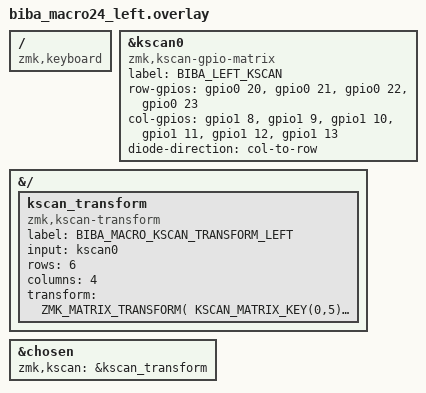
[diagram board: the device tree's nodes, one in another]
/dts-v1/;
/ {
    compatible = "zmk,keyboard";
};

/* LEFT PCB pins — replace with your actual Biba40 left-half pins */
&kscan0 {
    compatible = "zmk,kscan-gpio-matrix";
    label = "BIBA_LEFT_KSCAN";

    /* Example: old matrix 4 rows × 6 cols */
    row-gpios = <&gpio0 20 GPIO_ACTIVE_HIGH>,
                <&gpio0 21 GPIO_ACTIVE_HIGH>,
                <&gpio0 22 GPIO_ACTIVE_HIGH>,
                <&gpio0 23 GPIO_ACTIVE_HIGH>;

    col-gpios = <&gpio1 8 GPIO_ACTIVE_HIGH>,
                <&gpio1 9 GPIO_ACTIVE_HIGH>,
                <&gpio1 10 GPIO_ACTIVE_HIGH>,
                <&gpio1 11 GPIO_ACTIVE_HIGH>,
                <&gpio1 12 GPIO_ACTIVE_HIGH>,
                <&gpio1 13 GPIO_ACTIVE_HIGH>;

    diode-direction = "col-to-row";
};

/* Rotate 90° counter-clockwise: new(r,c) -> old(c, 5 - r) for old 4×6 */
&{/} {
    kscan_transform: kscan_transform {
        compatible = "zmk,kscan-transform";
        label = "BIBA_MACRO_KSCAN_TRANSFORM_LEFT";
        input = <&kscan0>;
        rows = <6>;
        columns = <4>;
        transform = <ZMK_MATRIX_TRANSFORM(
            KSCAN_MATRIX_KEY(0,5), KSCAN_MATRIX_KEY(1,5), KSCAN_MATRIX_KEY(2,5), KSCAN_MATRIX_KEY(3,5),
            KSCAN_MATRIX_KEY(0,4), KSCAN_MATRIX_KEY(1,4), KSCAN_MATRIX_KEY(2,4), KSCAN_MATRIX_KEY(3,4),
            KSCAN_MATRIX_KEY(0,3), KSCAN_MATRIX_KEY(1,3), KSCAN_MATRIX_KEY(2,3), KSCAN_MATRIX_KEY(3,3),
            KSCAN_MATRIX_KEY(0,2), KSCAN_MATRIX_KEY(1,2), KSCAN_MATRIX_KEY(2,2), KSCAN_MATRIX_KEY(3,2),
            KSCAN_MATRIX_KEY(0,1), KSCAN_MATRIX_KEY(1,1), KSCAN_MATRIX_KEY(2,1), KSCAN_MATRIX_KEY(3,1),
            KSCAN_MATRIX_KEY(0,0), KSCAN_MATRIX_KEY(1,0), KSCAN_MATRIX_KEY(2,0), KSCAN_MATRIX_KEY(3,0)
        )>;
    };
};

&chosen { zmk,kscan = &kscan_transform; };
